# EMU_CM register map
Vendor: Texas Instruments
Peripheral module from a debugger description file (folder omap4430).
Registers are 32-bit, access not given, reset 0x2 unless marked. A register's access mark holds for its fields unless they carry their own. Offsets are as the file gives them; lines under a group give offsets from that group; [hi:lo] are bit positions; {n}, {i} and the like mark numbered series; 'fields as' and 'values as' point back to an identical list; <NAME> marks a mode.

## EMU_CM
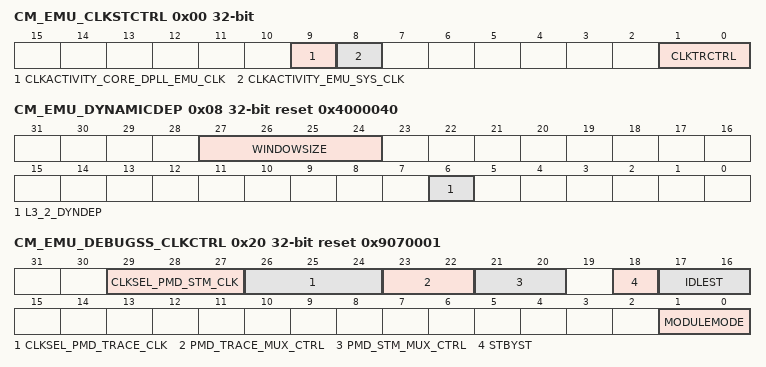
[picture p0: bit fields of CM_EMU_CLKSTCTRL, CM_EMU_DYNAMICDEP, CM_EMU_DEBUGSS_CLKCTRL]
0x00 CM_EMU_CLKSTCTRL access per field — This register enables the EMU domain power state transition. It controls the hardware supervised domain power state transition between ON-ACTIVE and ON-INACTIVE states. It also holds 1 status bit per clock input of the domain. [warm reset insensitive]
  [9] CLKACTIVITY_CORE_DPLL_EMU_CLK ro — This field indicates the state of the CORE_DPLL_EMU_CLK clock in the domain.
    0=CLKACTIVITY_CORE_DPLL_EMU_CLK_0_r (Corresponding clock is definitely gated); 1=CLKACTIVITY_CORE_DPLL_EMU_CLK_1_r (Corresponding clock is running or gating/ungating transition is ongoing)
  [8] CLKACTIVITY_EMU_SYS_CLK ro — This field indicates the state of the EMU_SYS_CLK clock in the domain.
    0=CLKACTIVITY_EMU_SYS_CLK_0_r (Corresponding clock is definitely gated); 1=CLKACTIVITY_EMU_SYS_CLK_1_r (Corresponding clock is running or gating/ungating transition is ongoing)
  [1:0] CLKTRCTRL rw — Controls the clock state transition of the EMU clock domain.
    0=CLKTRCTRL_0_r (Reserved); 1=CLKTRCTRL_1_r (Reserved); 2=SW_WKUP: Start a software forced wake-up transition on the domain; 3=HW_AUTO: Automatic transition is enabled. Sleep and wakeup transition are based upon hardware conditions.
0x08 CM_EMU_DYNAMICDEP reset 0x4000040 — This register controls the dynamic domain depedencies from EMU domain towards 'target' domains. It is relevant only for domain having INTRCONN master port(s).
  [27:24] WINDOWSIZE rw — Size of sliding window used to monitor INTRCONN interface activity for determination of auto-sleep feature. Time unit defined byCM_DYN_DEP_PRESCAL register.
  [6] L3_2_DYNDEP — Dynamic dependency towards L3_2 clock domain (access R Rreturns1s)
    1=L3_2_DYNDEP_1_r (Dependency is enabled)
0x20 CM_EMU_DEBUGSS_CLKCTRL reset 0x9070001 — This register manages the DEBUGSS clocks. [warm reset insensitive]
  [29:27] CLKSEL_PMD_STM_CLK rw — Selection of STM clock division
    0=CLKSEL_PMD_STM_CLK_0_r (Reserved); 1=STM_CLK is the selected STM source clock divided by 1; 2=STM_CLK is the selected STM source clock divided by 2; 3=CLKSEL_PMD_STM_CLK_3_r (Reserved); 4=STM_CLK is the selected STM source clock divided by 4; 5=CLKSEL_PMD_STM_CLK_5_r (Reserved); 6=CLKSEL_PMD_STM_CLK_6_r (Reserved); 7=CLKSEL_PMD_STM_CLK_7_r (Reserved)
  [26:24] CLKSEL_PMD_TRACE_CLK rw — Selection of TRACE clock division
    0=CLKSEL_PMD_TRACE_CLK_0_r (Reserved); 1=TRACE_CLK is the selected TRACE source clock divided by 1; 2=TRACE_CLK is the selected TRACE source clock divided by 2; 3=CLKSEL_PMD_TRACE_CLK_3_r (Reserved); 4=TRACE_CLK is the selected TRACE source clock divided by 4; 5=CLKSEL_PMD_TRACE_CLK_5_r (Reserved); 6=CLKSEL_PMD_TRACE_CLK_6_r (Reserved); 7=CLKSEL_PMD_TRACE_CLK_7_r (Reserved)
  [23:22] PMD_TRACE_MUX_CTRL rw — Selection of TRACE source clock
    0=TRACE source clock is SYS_CLK; 1=TRACE source clock is CORE_DPLL_EMU_CLK; 2=PMD_TRACE_MUX_CTRL_2_r (Reserved); 3=PMD_TRACE_MUX_CTRL_3_r (Reserved)
  [21:20] PMD_STM_MUX_CTRL rw — Selection of STM source clock
    0=STM source clock is SYS_CLK; 1=STM source clock is CORE_DPLL_EMU_CLK; 2=PMD_STM_MUX_CTRL_2_r (Reserved); 3=PMD_STM_MUX_CTRL_3_r (Reserved)
  [18] STBYST ro — Module standby status
    0=STBYST_0_r (Module is functional (not in standby)); 1=STBYST_1_r (Module is in standby)
  [17:16] IDLEST ro — Module idle status
    0=IDLEST_0_r (Module is fully functional, including INTRCONN); 1=IDLEST_1_r (Module is performing transition: wakeup, or sleep, or sleep abortion); 2=IDLEST_2_r (Module is in idle mode (only INTRCONN part). It is functional if using separate functional clock); 3=IDLEST_3_r (Module is disabled and cannot be accessed)
  [1:0] MODULEMODE — Control the way mandatory clocks are managed. (access R Rreturns)
    1=MODULEMODE_1_r (Module is managed automatically by hardware according to clock domain transition. A clock domain sleep transition put module into idle. A wakeup domain transition put it back into function. If CLKTRCTRL=3, any INTRCONN access to module is always granted. Module clocks may be gated according to the clock domain state.)
